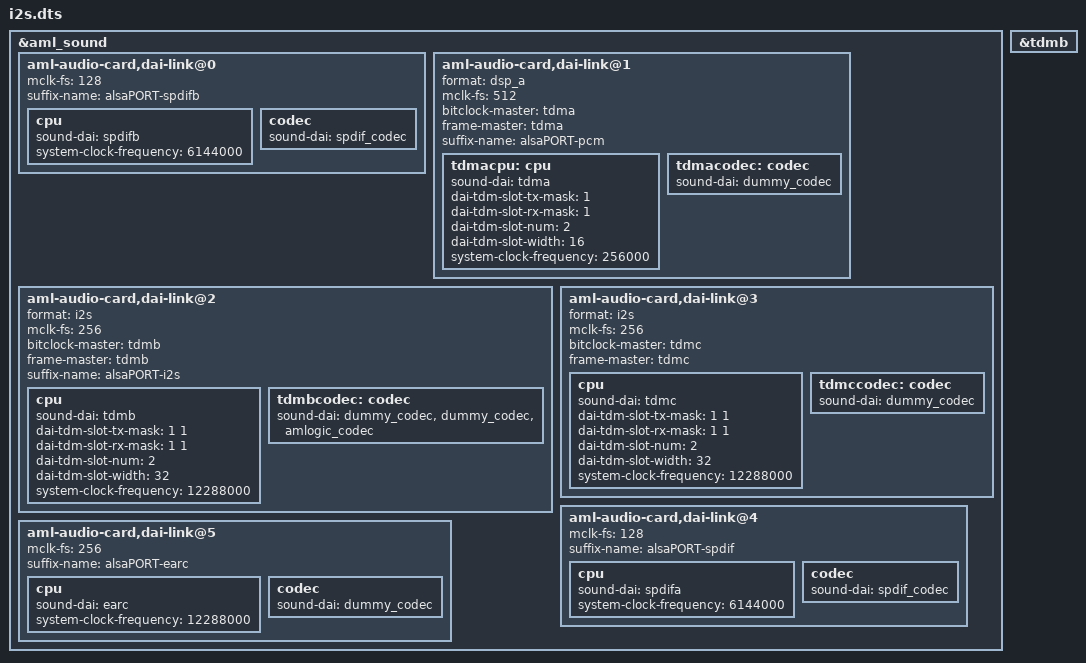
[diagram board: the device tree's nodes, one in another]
/dts-v1/;
/plugin/;

/ {
	fragment@0 {
		target = <&aml_sound>;

		__overlay__ {
			aml-audio-card,dai-link@0 {
				mclk-fs = <128>;
				/* suffix-name, sync with android audio hal
				 * what's the dai link used for
				 */
				suffix-name = "alsaPORT-spdifb";
				cpu {
					sound-dai = <&spdifb>;
					system-clock-frequency = <6144000>;
				};
				codec {
					sound-dai = <&spdif_codec>;
				};
			};

			aml-audio-card,dai-link@1 {
				format = "dsp_a";
				mclk-fs = <512>;
				//continuous-clock;
				//bitclock-inversion;
				//frame-inversion;
				/* master mode */
				bitclock-master = <&tdma>;
				frame-master = <&tdma>;
				/* slave mode */
				/*
				 * bitclock-master = <&tdmacodec>;
				 * frame-master = <&tdmacodec>;
				 */
				suffix-name = "alsaPORT-pcm";
				tdmacpu: cpu {
					sound-dai = <&tdma>;
					dai-tdm-slot-tx-mask =
								<1>;
					dai-tdm-slot-rx-mask =
								<1>;
					dai-tdm-slot-num = <2>;
					dai-tdm-slot-width = <16>;
					system-clock-frequency = <256000>;
				};
				tdmacodec: codec {
					sound-dai = <&dummy_codec>;
				};
			};

			aml-audio-card,dai-link@2 {
				format = "i2s";// "dsp_a";
				mclk-fs = <256>;
				//continuous-clock;
				//bitclock-inversion;
				//frame-inversion;
				/* master mode */
				bitclock-master = <&tdmb>;
				frame-master = <&tdmb>;
				/* slave mode */
				//bitclock-master = <&tdmbcodec>;
				//frame-master = <&tdmbcodec>;
				/* suffix-name, sync with android audio hal
				 * what's the dai link used for
				 */
				suffix-name = "alsaPORT-i2s";
				cpu {
					sound-dai = <&tdmb>;
					dai-tdm-slot-tx-mask = <1 1>;
					dai-tdm-slot-rx-mask = <1 1>;
					dai-tdm-slot-num = <2>;
					/*
					 * dai-tdm-slot-tx-mask =
					 *	<1 1 1 1 1 1 1 1>;
					 * dai-tdm-slot-rx-mask =
					 *	<1 1 1 1 1 1 1 1>;
					 * dai-tdm-slot-num = <8>;
					 */
					dai-tdm-slot-width = <32>;
					system-clock-frequency = <12288000>;
				};
				tdmbcodec: codec {
					sound-dai = <&dummy_codec &dummy_codec
					&amlogic_codec>;
				};
			};

			aml-audio-card,dai-link@3 {
				format = "i2s";
				mclk-fs = <256>;
				//continuous-clock;
				//bitclock-inversion;
				//frame-inversion;
				/* master mode */
				bitclock-master = <&tdmc>;
				frame-master = <&tdmc>;
				/* slave mode */
				//bitclock-master = <&tdmccodec>;
				//frame-master = <&tdmccodec>;
				/* suffix-name, sync with android audio hal used for */
				//suffix-name = "alsaPORT-tdm";
				cpu {
					sound-dai = <&tdmc>;
					dai-tdm-slot-tx-mask = <1 1>;
					dai-tdm-slot-rx-mask = <1 1>;
					dai-tdm-slot-num = <2>;
					dai-tdm-slot-width = <32>;
					system-clock-frequency = <12288000>;
				};
				tdmccodec: codec {
					sound-dai = <&dummy_codec>;
				};
			};

			aml-audio-card,dai-link@4 {
				mclk-fs = <128>;
				/* suffix-name, sync with android audio hal used for */
				suffix-name = "alsaPORT-spdif";
				cpu {
					sound-dai = <&spdifa>;
					system-clock-frequency = <6144000>;
				};
				codec {
					sound-dai = <&spdif_codec>;
				};
			};

			aml-audio-card,dai-link@5 {
				mclk-fs = <256>;
				suffix-name = "alsaPORT-earc";
				cpu {
					sound-dai = <&earc>;
					system-clock-frequency = <12288000>;
				};
				codec {
					sound-dai = <&dummy_codec>;
				};
			};
		};
	};

	fragment@1 {
		target = <&tdmb>;

		__overlay__ {
			status = "okay";
		};
	};
};
